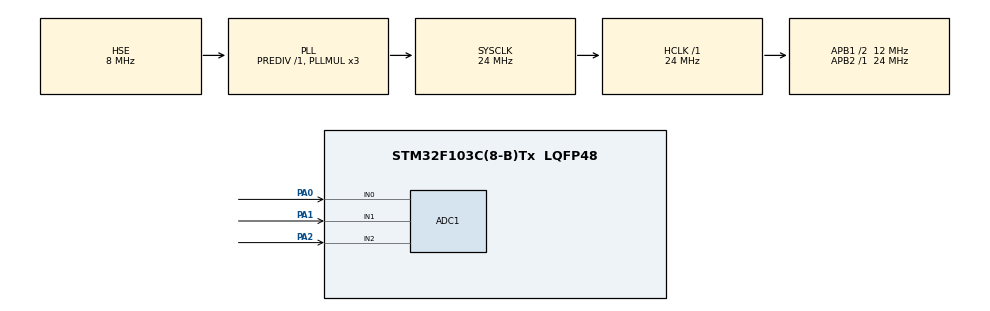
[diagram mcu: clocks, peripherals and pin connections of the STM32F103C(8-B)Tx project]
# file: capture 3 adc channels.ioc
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ADC1.Channel-3\#ChannelRegularConversion=ADC_CHANNEL_0
ADC1.Channel-4\#ChannelRegularConversion=ADC_CHANNEL_0
ADC1.Channel-5\#ChannelRegularConversion=ADC_CHANNEL_0
ADC1.EnableRegularConversion=ENABLE
ADC1.ExternalTrigConv=ADC_EXTERNALTRIGCONV_T3_TRGO
ADC1.NbrOfConversion=3
ADC1.NbrOfConversionFlag=1
ADC1.Rank-3\#ChannelRegularConversion=1
ADC1.Rank-4\#ChannelRegularConversion=2
ADC1.Rank-5\#ChannelRegularConversion=3
ADC1.SamplingTime-3\#ChannelRegularConversion=ADC_SAMPLETIME_1CYCLE_5
ADC1.SamplingTime-4\#ChannelRegularConversion=ADC_SAMPLETIME_1CYCLE_5
ADC1.SamplingTime-5\#ChannelRegularConversion=ADC_SAMPLETIME_1CYCLE_5
ADC1.master=1
Dma.ADC1.0.Direction=DMA_PERIPH_TO_MEMORY
Dma.ADC1.0.Instance=DMA1_Channel1
Dma.ADC1.0.MemDataAlignment=DMA_MDATAALIGN_HALFWORD
Dma.ADC1.0.MemInc=DMA_MINC_ENABLE
Dma.ADC1.0.Mode=DMA_CIRCULAR
Dma.ADC1.0.PeriphDataAlignment=DMA_PDATAALIGN_HALFWORD
Dma.ADC1.0.PeriphInc=DMA_PINC_DISABLE
Dma.ADC1.0.Priority=DMA_PRIORITY_LOW
Dma.Request0=ADC1
Mcu.Family=STM32F1
Mcu.Name=STM32F103C(8-B)Tx
Mcu.Package=LQFP48
NVIC.DMA1_Channel1_IRQn=true\:0\:0\:false\:false\:true\:false\:true\:true
NVIC.PriorityGroup=NVIC_PRIORITYGROUP_4
NVIC.TIM3_IRQn=true\:0\:0\:false\:false\:true\:true\:true\:true
PA0-WKUP.Signal=ADCx_IN0
PA1.Signal=ADCx_IN1
PA13.Mode=Serial_Wire
PA13.Signal=SYS_JTMS-SWDIO
PA14.Mode=Serial_Wire
PA14.Signal=SYS_JTCK-SWCLK
PA2.Signal=ADCx_IN2
PD0-OSC_IN.Mode=HSE-External-Oscillator
PD0-OSC_IN.Signal=RCC_OSC_IN
PD1-OSC_OUT.Mode=HSE-External-Oscillator
PD1-OSC_OUT.Signal=RCC_OSC_OUT
ProjectManager.HeapSize=0x200
ProjectManager.StackSize=0x400
ProjectManager.TargetToolchain=STM32CubeIDE
RCC.AHBFreq_Value=24000000
RCC.APB1CLKDivider=RCC_HCLK_DIV2
RCC.APB1Freq_Value=12000000
RCC.APB1TimFreq_Value=24000000
RCC.APB2Freq_Value=24000000
RCC.APB2TimFreq_Value=24000000
RCC.HCLKFreq_Value=24000000
RCC.PLLMUL=RCC_PLL_MUL3
RCC.PLLSourceVirtual=RCC_PLLSOURCE_HSE
RCC.SYSCLKFreq_VALUE=24000000
RCC.SYSCLKSource=RCC_SYSCLKSOURCE_PLLCLK
RCC.USBFreq_Value=24000000
SH.ADCx_IN0.0=ADC1_IN0,IN0
SH.ADCx_IN1.0=ADC1_IN1,IN1
SH.ADCx_IN2.0=ADC1_IN2,IN2
TIM3.Period=507
TIM3.Prescaler=71
TIM3.TIM_MasterOutputTrigger=TIM_TRGO_UPDATE
VP_TIM3_VS_ClockSourceINT.Mode=Internal
board=custom

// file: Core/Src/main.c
/* USER CODE BEGIN Header */
/**
 ******************************************************************************
 * @file           : main.c
 * @brief          : Main program body
 ******************************************************************************
 * @attention
 *
 * Copyright (c) 2024 STMicroelectronics.
 * All rights reserved.
 *
 * This software is licensed under terms that can be found in the LICENSE file
 * in the root directory of this software component.
 * If no LICENSE file comes with this software, it is provided AS-IS.
 *
 ******************************************************************************
 */
/* USER CODE END Header */
#include "main.h"

ADC_HandleTypeDef hadc1;
DMA_HandleTypeDef hdma_adc1;

TIM_HandleTypeDef htim3;

/* USER CODE BEGIN PV */
uint16_t adc_data_buffer[3];
void ADC_CONVERSION_COMPLETE(ADC_HandleTypeDef *hadc);

/* USER CODE END PV */

void SystemClock_Config(void);
static void MX_GPIO_Init(void);
static void MX_DMA_Init(void);
static void MX_ADC1_Init(void);
static void MX_TIM3_Init(void);

int main(void) {

	/* MCU Configuration--------------------------------------------------------*/

	/* Reset of all peripherals, Initializes the Flash interface and the Systick. */
	HAL_Init();

	/* Configure the system clock */
	SystemClock_Config();

	/* Initialize all configured peripherals */
	MX_GPIO_Init();
	MX_DMA_Init();
	MX_ADC1_Init();
	MX_TIM3_Init();
	/* USER CODE BEGIN 2 */
	HAL_ADC_RegisterCallback(&hadc1, HAL_ADC_CONVERSION_COMPLETE_CB_ID,
			ADC_CONVERSION_COMPLETE);
	HAL_ADC_Start_DMA(&hadc1, (uint32_t*) adc_data_buffer, 3);
//kda ana 3amalt arm lel adc ma3mltesh trigger fa enta lazem te3ml lel adc arm
	//we ba3d kda teshaghal al timer
	HAL_TIM_Base_Start(&htim3);
	/* USER CODE END 2 */

	/* Infinite loop */
	while (1) {

	}
}

void SystemClock_Config(void) {
	RCC_OscInitTypeDef RCC_OscInitStruct = { 0 };
	RCC_ClkInitTypeDef RCC_ClkInitStruct = { 0 };
	RCC_PeriphCLKInitTypeDef PeriphClkInit = { 0 };

	/** Initializes the RCC Oscillators according to the specified parameters
	 * in the RCC_OscInitTypeDef structure.
	 */
	RCC_OscInitStruct.OscillatorType = RCC_OSCILLATORTYPE_HSE;
	RCC_OscInitStruct.HSEState = RCC_HSE_ON;
	RCC_OscInitStruct.HSEPredivValue = RCC_HSE_PREDIV_DIV1;
	RCC_OscInitStruct.HSIState = RCC_HSI_ON;
	RCC_OscInitStruct.PLL.PLLState = RCC_PLL_ON;
	RCC_OscInitStruct.PLL.PLLSource = RCC_PLLSOURCE_HSE;
	RCC_OscInitStruct.PLL.PLLMUL = RCC_PLL_MUL3;
	if (HAL_RCC_OscConfig(&RCC_OscInitStruct) != HAL_OK) {
		Error_Handler();
	}

	/** Initializes the CPU, AHB and APB buses clocks
	 */
	RCC_ClkInitStruct.ClockType = RCC_CLOCKTYPE_HCLK | RCC_CLOCKTYPE_SYSCLK
			| RCC_CLOCKTYPE_PCLK1 | RCC_CLOCKTYPE_PCLK2;
	RCC_ClkInitStruct.SYSCLKSource = RCC_SYSCLKSOURCE_PLLCLK;
	RCC_ClkInitStruct.AHBCLKDivider = RCC_SYSCLK_DIV1;
	RCC_ClkInitStruct.APB1CLKDivider = RCC_HCLK_DIV2;
	RCC_ClkInitStruct.APB2CLKDivider = RCC_HCLK_DIV1;

	if (HAL_RCC_ClockConfig(&RCC_ClkInitStruct, FLASH_LATENCY_0) != HAL_OK) {
		Error_Handler();
	}
	PeriphClkInit.PeriphClockSelection = RCC_PERIPHCLK_ADC;
	PeriphClkInit.AdcClockSelection = RCC_ADCPCLK2_DIV2;
	if (HAL_RCCEx_PeriphCLKConfig(&PeriphClkInit) != HAL_OK) {
		Error_Handler();
	}
}

static void MX_ADC1_Init(void) {

	ADC_ChannelConfTypeDef sConfig = { 0 };

	/** Common config
	 */
	hadc1.Instance = ADC1;
	hadc1.Init.ScanConvMode = ADC_SCAN_ENABLE;
	hadc1.Init.ContinuousConvMode = DISABLE;
	hadc1.Init.DiscontinuousConvMode = DISABLE;
	hadc1.Init.ExternalTrigConv = ADC_EXTERNALTRIGCONV_T3_TRGO;
	hadc1.Init.DataAlign = ADC_DATAALIGN_RIGHT;
	hadc1.Init.NbrOfConversion = 3;
	if (HAL_ADC_Init(&hadc1) != HAL_OK) {
		Error_Handler();
	}

	/** Configure Regular Channel
	 */
	sConfig.Channel = ADC_CHANNEL_0;
	sConfig.Rank = ADC_REGULAR_RANK_1;
	sConfig.SamplingTime = ADC_SAMPLETIME_1CYCLE_5;
	if (HAL_ADC_ConfigChannel(&hadc1, &sConfig) != HAL_OK) {
		Error_Handler();
	}

	/** Configure Regular Channel
	 */
	sConfig.Rank = ADC_REGULAR_RANK_2;
	if (HAL_ADC_ConfigChannel(&hadc1, &sConfig) != HAL_OK) {
		Error_Handler();
	}

	/** Configure Regular Channel
	 */
	sConfig.Rank = ADC_REGULAR_RANK_3;
	if (HAL_ADC_ConfigChannel(&hadc1, &sConfig) != HAL_OK) {
		Error_Handler();
	}

}

static void MX_TIM3_Init(void) {

	TIM_ClockConfigTypeDef sClockSourceConfig = { 0 };
	TIM_MasterConfigTypeDef sMasterConfig = { 0 };

	htim3.Instance = TIM3;
	htim3.Init.Prescaler = 71;
	htim3.Init.CounterMode = TIM_COUNTERMODE_UP;
	htim3.Init.Period = 507;
	htim3.Init.ClockDivision = TIM_CLOCKDIVISION_DIV1;
	htim3.Init.AutoReloadPreload = TIM_AUTORELOAD_PRELOAD_DISABLE;
	if (HAL_TIM_Base_Init(&htim3) != HAL_OK) {
		Error_Handler();
	}
	sClockSourceConfig.ClockSource = TIM_CLOCKSOURCE_INTERNAL;
	if (HAL_TIM_ConfigClockSource(&htim3, &sClockSourceConfig) != HAL_OK) {
		Error_Handler();
	}
	sMasterConfig.MasterOutputTrigger = TIM_TRGO_UPDATE;
	sMasterConfig.MasterSlaveMode = TIM_MASTERSLAVEMODE_DISABLE;
	if (HAL_TIMEx_MasterConfigSynchronization(&htim3, &sMasterConfig)
			!= HAL_OK) {
		Error_Handler();
	}

}

static void MX_DMA_Init(void) {

	/* DMA controller clock enable */
	__HAL_RCC_DMA1_CLK_ENABLE();

	/* DMA interrupt init */
	/* DMA1_Channel1_IRQn interrupt configuration */
	HAL_NVIC_SetPriority(DMA1_Channel1_IRQn, 0, 0);
	HAL_NVIC_EnableIRQ(DMA1_Channel1_IRQn);

}

static void MX_GPIO_Init(void) {

	/* GPIO Ports Clock Enable */
	__HAL_RCC_GPIOD_CLK_ENABLE();
	__HAL_RCC_GPIOA_CLK_ENABLE();

}

/* USER CODE BEGIN 4 */
void ADC_CONVERSION_COMPLETE(ADC_HandleTypeDef *hadc) {
}

/* USER CODE END 4 */

void Error_Handler(void) {
	__disable_irq();
	while (1) {
	}
}
